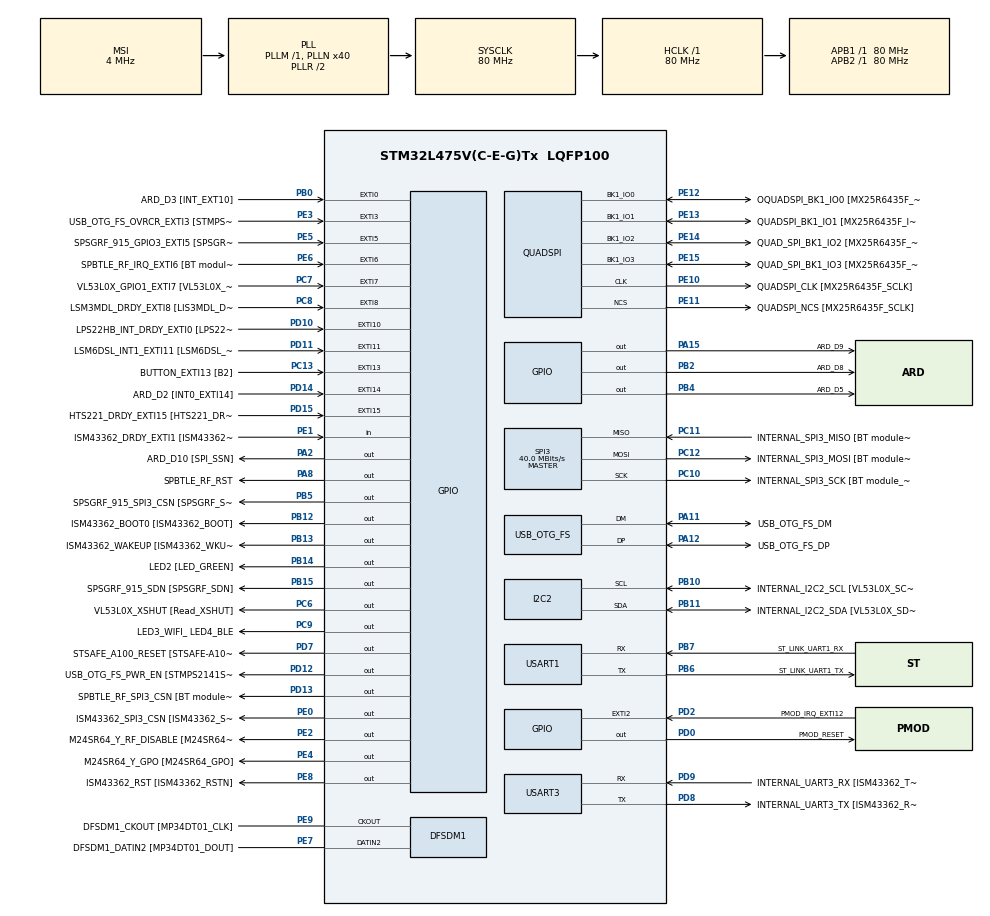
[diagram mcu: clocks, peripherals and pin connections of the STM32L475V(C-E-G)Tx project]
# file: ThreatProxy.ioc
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Mcu.Family=STM32L4
Mcu.Name=STM32L475V(C-E-G)Tx
Mcu.Package=LQFP100
NVIC.EXTI15_10_IRQn=true\:0\:0\:false\:false\:true\:true\:true\:true
NVIC.EXTI9_5_IRQn=true\:0\:0\:false\:false\:true\:true\:true\:true
NVIC.PriorityGroup=NVIC_PRIORITYGROUP_4
PA0.GPIO_Label=ARD_D1 [UART4_TX]
PA0.Signal=UART4_TX
PA1.GPIO_Label=ARD_D0 [UART4_RX]
PA1.Signal=UART4_RX
PA10.GPIO_Label=USB_OTG_FS_ID
PA10.Signal=USB_OTG_FS_ID
PA11.GPIO_Label=USB_OTG_FS_DM
PA11.Mode=Device_Only
PA11.Signal=USB_OTG_FS_DM
PA12.GPIO_Label=USB_OTG_FS_DP
PA12.Mode=Device_Only
PA12.Signal=USB_OTG_FS_DP
PA13\ (JTMS-SWDIO).GPIO_Label=SYS_JTMS_SWDIO
PA13\ (JTMS-SWDIO).Mode=Serial_Wire
PA13\ (JTMS-SWDIO).Signal=SYS_JTMS-SWDIO
PA14\ (JTCK-SWCLK).GPIO_Label=SYS_JTCK_SWCLK
PA14\ (JTCK-SWCLK).Mode=Serial_Wire
PA14\ (JTCK-SWCLK).Signal=SYS_JTCK-SWCLK
PA15\ (JTDI).GPIO_Label=ARD_D9
PA15\ (JTDI).Signal=GPIO_Output
PA2.GPIO_Label=ARD_D10 [SPI_SSN]
PA2.Signal=GPIO_Output
PA3.GPIO_Label=ARD_D4
PA3.Signal=S_TIM2_CH4
PA4.GPIO_Label=ARD_D7
PA4.Signal=ADCx_IN9
PA5.GPIO_Label=ARD_D13 [SPI1_SCK]
PA5.Signal=SPI1_SCK
PA6.GPIO_Label=ARD_D12 [SPI1_MISO]
PA6.Signal=SPI1_MISO
PA7.GPIO_Label=ARD_D11 [SPI1_MOSI]
PA7.Signal=SPI1_MOSI
PA8.GPIO_Label=SPBTLE_RF_RST
PA8.Signal=GPIO_Output
PA9.GPIO_Label=USB_OTG_FS_VBUS [STMPS2141STR_OUT]
PA9.Signal=USB_OTG_FS_VBUS
PB0.GPIO_Label=ARD_D3 [INT_EXT10]
PB0.Signal=GPXTI0
PB1.GPIO_Label=ARD_D6 [ADC1_IN6]
PB1.Signal=ADCx_IN16
PB10.GPIO_Label=INTERNAL_I2C2_SCL [VL53L0X_SCL]
PB10.GPIO_Pu=GPIO_PULLUP
PB10.Mode=I2C
PB10.Signal=I2C2_SCL
PB11.GPIO_Label=INTERNAL_I2C2_SDA [VL53L0X_SDA]
PB11.GPIO_Pu=GPIO_PULLUP
PB11.Mode=I2C
PB11.Signal=I2C2_SDA
PB12.GPIO_Label=ISM43362_BOOT0 [ISM43362_BOOT]
PB12.Signal=GPIO_Output
PB13.GPIO_Label=ISM43362_WAKEUP [ISM43362_WKUP]
PB13.Signal=GPIO_Output
PB14.GPIO_Label=LED2 [LED_GREEN]
PB14.Signal=GPIO_Output
PB15.GPIO_Label=SPSGRF_915_SDN [SPSGRF_SDN]
PB15.Signal=GPIO_Output
PB2.GPIO_Label=ARD_D8
PB2.Signal=GPIO_Output
PB3\ (JTDO-TRACESWO).GPIO_Label=SYS_JTD0_SWO
PB3\ (JTDO-TRACESWO).Signal=SYS_JTDO-SWO
PB4\ (NJTRST).GPIO_Label=ARD_D5
PB4\ (NJTRST).Signal=GPIO_Output
PB5.GPIO_Label=SPSGRF_915_SPI3_CSN [SPSGRF_SPI_CS]
PB5.PinState=GPIO_PIN_SET
PB5.Signal=GPIO_Output
PB6.GPIO_Label=ST_LINK_UART1_TX
PB6.Mode=Asynchronous
PB6.Signal=USART1_TX
PB7.GPIO_Label=ST_LINK_UART1_RX
PB7.Mode=Asynchronous
PB7.Signal=USART1_RX
PB8.GPIO_Label=ARD_D15 [I2C1_SCL]
PB8.Signal=I2C1_SCL
PB9.GPIO_Label=ARD_D14 [I2C1_SDA]
PB9.Signal=I2C1_SDA
PC0.GPIO_Label=ARD_A5 [ADC]
PC0.Signal=ADCx_IN1
PC1.GPIO_Label=ARD_A4 [ADC]
PC1.Signal=ADCx_IN2
PC10.GPIO_Label=INTERNAL_SPI3_SCK [BT module_SPI_SCLK] [ISM43362_SCK]
PC10.Mode=Full_Duplex_Master
PC10.Signal=SPI3_SCK
PC11.GPIO_Label=INTERNAL_SPI3_MISO [BT module_SPI_MISO] [ISM43362_MISO]
PC11.Mode=Full_Duplex_Master
PC11.Signal=SPI3_MISO
PC12.GPIO_Label=INTERNAL_SPI3_MOSI [BT module_SPI_MOSI] [ISM43362_MOSI]
PC12.Mode=Full_Duplex_Master
PC12.Signal=SPI3_MOSI
PC13.GPIO_Label=BUTTON_EXTI13 [B2]
PC13.GPIO_ModeDefaultEXTI=GPIO_MODE_IT_FALLING
PC13.Signal=GPXTI13
PC14-OSC32_IN\ (PC14).Mode=LSE-External-Oscillator
PC14-OSC32_IN\ (PC14).Signal=RCC_OSC32_IN
PC15-OSC32_OUT\ (PC15).Mode=LSE-External-Oscillator
PC15-OSC32_OUT\ (PC15).Signal=RCC_OSC32_OUT
PC2.GPIO_Label=ARD_A3 [ADC]
PC2.Signal=ADCx_IN3
PC3.GPIO_Label=ARD_A2 [ADC]
PC3.Signal=ADCx_IN4
PC4.GPIO_Label=ARD_A1 [ADC]
PC4.Signal=ADCx_IN13
PC5.GPIO_Label=ARD_A0 [ADC]
PC5.Signal=ADCx_IN14
PC6.GPIO_Label=VL53L0X_XSHUT [Read_XSHUT]
PC6.Signal=GPIO_Output
PC7.GPIO_Label=VL53L0X_GPIO1_EXTI7 [VL53L0X_GPIO1]
PC7.Signal=GPXTI7
PC8.GPIO_Label=LSM3MDL_DRDY_EXTI8 [LIS3MDL_DRDY]
PC8.Signal=GPXTI8
PC9.GPIO_Label=LED3_WIFI_ LED4_BLE
PC9.Signal=GPIO_Output
PD0.GPIO_Label=PMOD_RESET
PD0.Signal=GPIO_Output
PD1.GPIO_Label=PMOD_SPI2_SCK
PD1.Signal=SPI2_SCK
PD10.GPIO_Label=LPS22HB_INT_DRDY_EXTI0 [LPS22HB_INT_DRDY] 
PD10.Signal=GPXTI10
PD11.GPIO_Label=LSM6DSL_INT1_EXTI11 [LSM6DSL_INT1]
PD11.Signal=GPXTI11
PD12.GPIO_Label=USB_OTG_FS_PWR_EN [STMPS2141STR_EN]
PD12.Signal=GPIO_Output
PD13.GPIO_Label=SPBTLE_RF_SPI3_CSN [BT module_SPI_CS]
PD13.PinState=GPIO_PIN_SET
PD13.Signal=GPIO_Output
PD14.GPIO_Label=ARD_D2 [INT0_EXTI14]
PD14.Signal=GPXTI14
PD15.GPIO_Label=HTS221_DRDY_EXTI15 [HTS221_DRDY]
PD15.Signal=GPXTI15
PD2.GPIO_Label=PMOD_IRQ_EXTI12
PD2.Signal=GPXTI2
PD3.GPIO_Label=PMOD_UART2_CTS
PD3.Signal=USART2_CTS
PD4.GPIO_Label=PMOD_UART2_RTS
PD4.Signal=USART2_RTS
PD5.GPIO_Label=PMOD_UART2_TX
PD5.Signal=USART2_TX
PD6.GPIO_Label=PMOD_UART2_RX
PD6.Signal=USART2_RX
PD7.GPIO_Label=STSAFE_A100_RESET [STSAFE-A100_RESET]
PD7.Signal=GPIO_Output
PD8.GPIO_Label=INTERNAL_UART3_TX [ISM43362_RX]
PD8.Mode=Asynchronous
PD8.Signal=USART3_TX
PD9.GPIO_Label=INTERNAL_UART3_RX [ISM43362_TX]
PD9.Mode=Asynchronous
PD9.Signal=USART3_RX
PE0.GPIO_Label=ISM43362_SPI3_CSN [ISM43362_SSN]
PE0.PinState=GPIO_PIN_SET
PE0.Signal=GPIO_Output
PE1.GPIO_Label=ISM43362_DRDY_EXTI1 [ISM43362_DATARDY]
PE1.Signal=GPIO_Input
PE10.GPIO_Label=QUADSPI_CLK [MX25R6435F_SCLK]
PE10.Mode=Single Bank
PE10.Signal=QUADSPI_CLK
PE11.GPIO_Label=QUADSPI_NCS [MX25R6435F_SCLK]
PE11.Mode=Single Bank
PE11.Signal=QUADSPI_NCS
PE12.GPIO_Label=OQUADSPI_BK1_IO0 [MX25R6435F_IO0]
PE12.Mode=Single Bank
PE12.Signal=QUADSPI_BK1_IO0
PE13.GPIO_Label=QUADSPI_BK1_IO1 [MX25R6435F_IO1]
PE13.Mode=Single Bank
PE13.Signal=QUADSPI_BK1_IO1
PE14.GPIO_Label=QUAD_SPI_BK1_IO2 [MX25R6435F_IO2]
PE14.Mode=Single Bank
PE14.Signal=QUADSPI_BK1_IO2
PE15.GPIO_Label=QUAD_SPI_BK1_IO3 [MX25R6435F_IO3]
PE15.Mode=Single Bank
PE15.Signal=QUADSPI_BK1_IO3
PE2.GPIO_Label=M24SR64_Y_RF_DISABLE [M24SR64_RFDIS]
PE2.Signal=GPIO_Output
PE3.GPIO_Label=USB_OTG_FS_OVRCR_EXTI3 [STMPS2141STR_FAULT]
PE3.Signal=GPXTI3
PE4.GPIO_Label=M24SR64_Y_GPO [M24SR64_GPO]
PE4.Signal=GPIO_Output
PE5.GPIO_Label=SPSGRF_915_GPIO3_EXTI5 [SPSGRF_GPIO_3]
PE5.Signal=GPXTI5
PE6.GPIO_Label=SPBTLE_RF_IRQ_EXTI6 [BT module_SPI_IRQ]
PE6.Signal=GPXTI6
PE7.GPIO_Label=DFSDM1_DATIN2 [MP34DT01_DOUT]
PE7.Signal=S_DATAIN2DFSDM1
PE8.GPIO_Label=ISM43362_RST [ISM43362_RSTN]
PE8.Signal=GPIO_Output
PE9.GPIO_Label=DFSDM1_CKOUT [MP34DT01_CLK]
PE9.Signal=S_CKOUTDFSDM1
ProjectManager.HeapSize=0x200
ProjectManager.StackSize=0x400
ProjectManager.TargetToolchain=CMake
QUADSPI.ClockPrescaler=2
QUADSPI.FifoThreshold=4
QUADSPI.FlashSize=23
QUADSPI.SampleShifting=QSPI_SAMPLE_SHIFTING_HALFCYCLE
RCC.ADCFreq_Value=48000000
RCC.AHBFreq_Value=80000000
RCC.APB1Freq_Value=80000000
RCC.APB1TimFreq_Value=80000000
RCC.APB2Freq_Value=80000000
RCC.APB2TimFreq_Value=80000000
RCC.CortexFreq_Value=80000000
RCC.HCLKFreq_Value=80000000
RCC.HSE_VALUE=8000000
RCC.HSI_VALUE=16000000
RCC.MSI_VALUE=4000000
RCC.PLLN=40
RCC.PLLSAI1N=24
RCC.SYSCLKFreq_VALUE=80000000
RCC.SYSCLKSource=RCC_SYSCLKSOURCE_PLLCLK
RCC.USBFreq_Value=48000000
RCC.VCOOutputFreq_Value=160000000
SH.ADCx_IN1.0=ADC1_IN1
SH.ADCx_IN13.0=ADC1_IN13
SH.ADCx_IN14.0=ADC1_IN14
SH.ADCx_IN16.0=ADC1_IN16
SH.ADCx_IN2.0=ADC1_IN2
SH.ADCx_IN3.0=ADC1_IN3
SH.ADCx_IN4.0=ADC1_IN4
SH.ADCx_IN9.0=ADC1_IN9
SH.S_CKOUTDFSDM1.0=DFSDM1_CKOUT,CKOUT
SH.S_CKOUTDFSDM1.1=DFSDM1_CKOUT,PDM_SPI_Input_from_ch12_and_Internal_Clock
SH.S_DATAIN2DFSDM1.0=DFSDM1_DATIN2,PDM_SPI_Input_from_ch12_and_Internal_Clock
SH.S_TIM2_CH4.0=TIM2_CH4
SPI3.CalculateBaudRate=40.0 MBits/s
SPI3.Direction=SPI_DIRECTION_2LINES
SPI3.Mode=SPI_MODE_MASTER
SPI3.VirtualType=VM_MASTER
USART1.VirtualMode-Asynchronous=VM_ASYNC
USART3.VirtualMode-Asynchronous=VM_ASYNC
USB_OTG_FS.VirtualMode=Device_Only
board=B-L475E-IOT01A1

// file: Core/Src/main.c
/* USER CODE BEGIN Header */
/**
  ******************************************************************************
  * @file           : main.c
  * @brief          : Main program body
  ******************************************************************************
  * @attention
  *
  * Copyright (c) 2026 STMicroelectronics.
  * All rights reserved.
  *
  * This software is licensed under terms that can be found in the LICENSE file
  * in the root directory of this software component.
  * If no LICENSE file comes with this software, it is provided AS-IS.
  *
  ******************************************************************************
  */
/* USER CODE END Header */
#include "main.h"
#include "secrets.h"
#include <string.h>
#include <stdlib.h>

DFSDM_Channel_HandleTypeDef hdfsdm1_channel1;

I2C_HandleTypeDef hi2c2;

QSPI_HandleTypeDef hqspi;

SPI_HandleTypeDef hspi3;

UART_HandleTypeDef huart1;
UART_HandleTypeDef huart3;

PCD_HandleTypeDef hpcd_USB_OTG_FS;

void SystemClock_Config(void);
static void MX_GPIO_Init(void);
static void MX_DFSDM1_Init(void);
static void MX_I2C2_Init(void);
static void MX_QUADSPI_Init(void);
static void MX_SPI3_Init(void);
static void MX_USART1_UART_Init(void);
static void MX_USART3_UART_Init(void);
static void MX_USB_OTG_FS_PCD_Init(void);

/* USER CODE BEGIN 0 */
#include <stdio.h>
int _write(int file, char *ptr, int len) {

    HAL_UART_Transmit(&huart1, (uint8_t *)ptr, len, HAL_MAX_DELAY);
    return len;
}
/* USER CODE END 0 */

void Inventek_Send_Command(SPI_HandleTypeDef *hspi, const char *cmd) {
    uint8_t tx_buf[128] = {0};
    uint16_t len = strlen(cmd);
    strcpy((char*)tx_buf, cmd);

    if (len % 2 != 0) {
        tx_buf[len] = '\n';
        len++;
    }

    for (int i = 0; i < len; i += 2) {
        uint8_t temp = tx_buf[i];
        tx_buf[i] = tx_buf[i+1];
        tx_buf[i+1] = temp;
    }

    HAL_GPIO_WritePin(GPIOE, GPIO_PIN_0, GPIO_PIN_RESET);
    HAL_Delay(1);
    HAL_SPI_Transmit(hspi, tx_buf, len, 100);
    HAL_GPIO_WritePin(GPIOE, GPIO_PIN_0, GPIO_PIN_SET);
    HAL_Delay(10);
}

void Inventek_Drain_Response(SPI_HandleTypeDef *hspi) {
    uint32_t wait_timeout = HAL_GetTick() + 1000;

    while(HAL_GPIO_ReadPin(GPIOE, GPIO_PIN_1) == GPIO_PIN_RESET && HAL_GetTick() < wait_timeout);

    if(HAL_GPIO_ReadPin(GPIOE, GPIO_PIN_1) == GPIO_PIN_SET) {
        HAL_GPIO_WritePin(GPIOE, GPIO_PIN_0, GPIO_PIN_RESET);
        uint8_t dummy[2] = {0x0A, 0x0A}, rx[2] = {0};
        uint32_t drain_timeout = HAL_GetTick() + 2000;

        printf("  -> Radio replied: ");
        while(HAL_GPIO_ReadPin(GPIOE, GPIO_PIN_1) == GPIO_PIN_SET && HAL_GetTick() < drain_timeout) {
            HAL_SPI_TransmitReceive(hspi, dummy, rx, 2, 10);

            if((rx[1] >= 0x20 && rx[1] <= 0x7E) || rx[1] == '\r' || rx[1] == '\n') printf("%c", rx[1]);
            if((rx[0] >= 0x20 && rx[0] <= 0x7E) || rx[0] == '\r' || rx[0] == '\n') printf("%c", rx[0]);
        }
        HAL_GPIO_WritePin(GPIOE, GPIO_PIN_0, GPIO_PIN_SET);
    } else {
        printf("  -> [!] No response from radio.\r\n");
    }
    HAL_Delay(50);
}

typedef struct {
    uint16_t magic;
    uint32_t src_ip;
    uint32_t dst_ip;
    uint16_t src_port;
    uint16_t dst_port;
    uint8_t  protocol;
} __attribute__((packed)) FlowTuple;

#define IP_PARTS(ip) (uint8_t)(ip), (uint8_t)((ip) >> 8), (uint8_t)((ip) >> 16), (uint8_t)((ip) >> 24)

uint32_t MurmurHash3_32(const void* key, int len, uint32_t seed) {
    const uint8_t* data = (const uint8_t*)key;
    const int nblocks = len / 4;
    uint32_t h1 = seed;
    const uint32_t c1 = 0xcc9e2d51;
    const uint32_t c2 = 0x1b873593;

    const uint32_t* blocks = (const uint32_t*)(data + nblocks * 4);
    for (int i = -nblocks; i; i++) {
        uint32_t k1 = blocks[i];
        k1 *= c1;
        k1 = (k1 << 15) | (k1 >> (32 - 15));
        k1 *= c2;

        h1 ^= k1;
        h1 = (h1 << 13) | (h1 >> (32 - 13));
        h1 = h1 * 5 + 0xe6546b64;
    }

    const uint8_t* tail = (const uint8_t*)(data + nblocks * 4);
    uint32_t k1 = 0;
    switch (len & 3) {
        case 3: k1 ^= tail[2] << 16;
        case 2: k1 ^= tail[1] << 8;
        case 1: k1 ^= tail[0];
                k1 *= c1;
                k1 = (k1 << 15) | (k1 >> (32 - 15));
                k1 *= c2;
                h1 ^= k1;
    }

    h1 ^= len;
    h1 ^= h1 >> 16;
    h1 *= 0x85ebca6b;
    h1 ^= h1 >> 13;
    h1 *= 0xc2b2ae35;
    h1 ^= h1 >> 16;

    return h1;
}

#define MAX_STATES 50
#define ALPHABET_SIZE 256

int goto_fn[MAX_STATES][ALPHABET_SIZE];
int out_fn[MAX_STATES];
int num_states = 1;
void build_aho_corasick() {
    memset(goto_fn, -1, sizeof(goto_fn));
    memset(out_fn, 0, sizeof(out_fn));

    // --- REAL CVE HEX SIGNATURES ---
    // 1. Log4Shell JNDI Trigger ("${jndi:")
    const uint8_t sig_log4j[] = {0x24, 0x7B, 0x6A, 0x6E, 0x64, 0x69, 0x3A};
    // 2. x86 Buffer Overflow (NOP Sled)
    const uint8_t sig_nop[]   = {0x90, 0x90, 0x90, 0x90, 0x90, 0x90, 0x90, 0x90};
    // 3. Heartbleed Malformed TLS Heartbeat
    const uint8_t sig_heart[] = {0x18, 0x03, 0x02, 0x00, 0x03};

    const uint8_t* signatures[] = {sig_log4j, sig_nop, sig_heart};
    const int sig_lengths[] = {sizeof(sig_log4j), sizeof(sig_nop), sizeof(sig_heart)};
    int num_signatures = 3;

    // Build the state machine strictly using raw byte values (0x00 - 0xFF)
    for (int i = 0; i < num_signatures; i++) {
        int curr_state = 0;
        for (int j = 0; j < sig_lengths[i]; j++) {
            uint8_t c = signatures[i][j]; // Extract exact hex byte
            if (goto_fn[curr_state][c] == -1) {
                goto_fn[curr_state][c] = num_states++;
            }
            curr_state = goto_fn[curr_state][c];
        }
        out_fn[curr_state] = 1;
    }

    for (int i = 0; i < ALPHABET_SIZE; i++) {
        if (goto_fn[0][i] == -1) goto_fn[0][i] = 0;
    }
}
//defined int goto_fn[MAX_STATES][256], created a grid in memory.The Y-axis is your current state.
// The X-axis has exactly 256 slots. This perfectly matches the 256 possible values of an 8-bit byte.
// When the processor reads a byte from the incoming payload let's say it reads 0x18  the first byte of the TLS Heartbleed trigger it does not ask, "
// Does 0x18 equal 0x18?" Instead, the processor takes the literal integer value of 0x18 (which is 24 in decimal) and uses it as the Column Number.It immediately
//  jumps to Row 0, Column 24 in the memory matrix. Sitting inside that exact cell is a pre-calculated integer telling the board what the next state is
//  brilliant for an edge proxy:Because the raw packet data is being used as a literal memory address pointer,
// the time complexity to evaluate a byte is $O(1)$. It takes exactly one clock cycle to fetch the next state, regardless of whether you have 3 signatures
//  loaded or 14,000
// When you create a 2D array in C like goto_fn[state][byte], the compiler translates that into a literal physical address in the RAM.
// When the processor reads a byte from the network (let's say 0x18), it does not loop through a list looking for 0x18. Instead, the ALUs
// inside the ARM Cortex execute a hardwired calculation:
int aho_corasick_search(const uint8_t* payload, int len) {
    int curr_state = 0;
    for (int i = 0; i < len; i++) {
        curr_state = goto_fn[curr_state][payload[i]];
        if (curr_state == -1) curr_state = 0;

        if (out_fn[curr_state]) {
            return i;
        }
    }
    return -1;
}

int main(void)
{

  /* MCU Configuration--------------------------------------------------------*/

  /* Reset of all peripherals, Initializes the Flash interface and the Systick. */
  HAL_Init();

  /* Configure the system clock */
  SystemClock_Config();

  /* Initialize all configured peripherals */
  MX_GPIO_Init();
  MX_DFSDM1_Init();
  MX_I2C2_Init();
  MX_QUADSPI_Init();
  MX_SPI3_Init();
  MX_USART1_UART_Init();
  MX_USART3_UART_Init();
  MX_USB_OTG_FS_PCD_Init();

  printf("\r\n[*]ISOLATING AND WAKING THE RADIO\r\n");

  HAL_GPIO_WritePin(GPIOB, GPIO_PIN_12, GPIO_PIN_RESET);

  HAL_GPIO_WritePin(GPIOE, GPIO_PIN_8, GPIO_PIN_RESET);
  HAL_Delay(50);

  HAL_GPIO_WritePin(GPIOB, GPIO_PIN_13, GPIO_PIN_SET);

  HAL_GPIO_WritePin(GPIOE, GPIO_PIN_0, GPIO_PIN_RESET);
  HAL_Delay(10);

  HAL_GPIO_WritePin(GPIOE, GPIO_PIN_8, GPIO_PIN_SET);

  HAL_Delay(50);

  HAL_GPIO_WritePin(GPIOE, GPIO_PIN_0, GPIO_PIN_SET);

  HAL_Delay(500);
  printf("[*] Draining internal boot prompt\r\n");
  Inventek_Drain_Response(&hspi3);
  printf("[*] Boot prompt cleared. Radio is ready.\r\n");

 printf("\r\n[*] Configuring Wi-Fi Credentials\r\n");
  char cmd_buffer[128];

  snprintf(cmd_buffer, sizeof(cmd_buffer), "C1=%s\r", WIFI_SSID);
  Inventek_Send_Command(&hspi3, cmd_buffer);
  Inventek_Drain_Response(&hspi3);

  snprintf(cmd_buffer, sizeof(cmd_buffer), "C2=%s\r", WIFI_PASS);
  Inventek_Send_Command(&hspi3, cmd_buffer);
  Inventek_Drain_Response(&hspi3);

  Inventek_Send_Command(&hspi3, "C3=3\r");
  Inventek_Drain_Response(&hspi3);

  Inventek_Send_Command(&hspi3, "C4=1\r");
  Inventek_Drain_Response(&hspi3);

  printf("\r\n[*] Attempting to join network and pull DHCP lease\r\n");
  Inventek_Send_Command(&hspi3, "C0\r");

  uint32_t join_timeout = HAL_GetTick() + 35000;
  uint8_t joined = 0;

  printf("\r\nLIVE NETWORK LOG\r\n");

  while(HAL_GetTick() < join_timeout && !joined) {

      if(HAL_GPIO_ReadPin(GPIOE, GPIO_PIN_1) == GPIO_PIN_SET) {

          HAL_GPIO_WritePin(GPIOE, GPIO_PIN_0, GPIO_PIN_RESET);

          uint8_t dummy_word[2] = {0x0A, 0x0A}, rx_word[2] = {0};
          uint32_t read_timeout = HAL_GetTick() + 2000;

          while(HAL_GPIO_ReadPin(GPIOE, GPIO_PIN_1) == GPIO_PIN_SET && HAL_GetTick() < read_timeout) {
              HAL_SPI_TransmitReceive(&hspi3, dummy_word, rx_word, 2, 10);

              if((rx_word[1] >= 0x20 && rx_word[1] <= 0x7E) || rx_word[1] == '\r' || rx_word[1] == '\n') {
                  printf("%c", rx_word[1]);

                  if(rx_word[1] == '>') joined = 1;
              }
              if((rx_word[0] >= 0x20 && rx_word[0] <= 0x7E) || rx_word[0] == '\r' || rx_word[0] == '\n') {
                  printf("%c", rx_word[0]);

                  if(rx_word[0] == '>') joined = 1;
              }
          }

          HAL_GPIO_WritePin(GPIOE, GPIO_PIN_0, GPIO_PIN_SET);
          HAL_Delay(50);
      }
  }

  printf("\r\nEND\r\n");

  Inventek_Send_Command(&hspi3, "P1=0\r");
  Inventek_Drain_Response(&hspi3);

  Inventek_Send_Command(&hspi3, "P2=54321\r");
  Inventek_Drain_Response(&hspi3);

  Inventek_Send_Command(&hspi3, "R1=1\r");
  Inventek_Drain_Response(&hspi3);

  Inventek_Send_Command(&hspi3, "P5=1\r");
  Inventek_Drain_Response(&hspi3);
  printf("\r\n[*] Compiling Aho-Corasick DPI State Machine\r\n");
  build_aho_corasick();

  printf("\r\n[*] Vertex Active. Awaiting Incoming Flows\r\n");

  static uint32_t last_heartbeat = 0;
  static uint32_t loop_counter = 0;

  while (1)
  {
      uint8_t demo_payload[53] = {
          0x55, 0xAA, // Magic Header
          0x00, 0x00, 0x00, 0x00, // Placeholder for Src IP
          0xC0, 0xA8, 0x01, 0xE9, // Dst IP: 192.168.1.233 (The Proxy VIP)
          0xC0, 0x00, // Src Port placeholder
          0xD3, 0xD4, // Dst Port: 54321
          0x06,       // Protocol: TCP
          // ... trailing payload bytes
      };

      // --- LIVE DISTRIBUTED ATTACK SIMULATION ---
      // Generate a completely random global Source IP to simulate a distributed botnet
      demo_payload[2] = (uint8_t)(rand() % 223 + 1); // 1-223 (Public IP ranges)
      demo_payload[3] = (uint8_t)(rand() % 256);
      demo_payload[4] = (uint8_t)(rand() % 256);
      demo_payload[5] = (uint8_t)(rand() % 256);

      FlowTuple current_flow;
      memcpy(&current_flow, &demo_payload[0], sizeof(FlowTuple));

      // Dynamically increment the port
      static uint16_t dynamic_src_port = 49152;
      current_flow.src_port = dynamic_src_port++;
      current_flow.dst_port = 54321;

      uint32_t flow_id = MurmurHash3_32(&current_flow.src_ip, sizeof(FlowTuple) - 2, 0x12345678);
      //route this flow without using a memoryheavy state table.
      // We take that extracted 5-Tuple and pass it by reference into a murmurhash3 algorithm. This is a noncryptographic hash function
      // optimized for silicon. It crushes the IP and Port data down into a highly unique, deterministic 32bit integer,
      // store here"

      printf("L4 FLOW INTERCEPTED \r\n");
      printf("Src IP: %u.%u.%u.%u | Dst IP: %u.%u.%u.%u \r\n",
             IP_PARTS(current_flow.src_ip), IP_PARTS(current_flow.dst_ip));
      printf("Protocol: %u | Src Port: %u | Dst Port: %u \r\n",
             current_flow.protocol, current_flow.src_port, current_flow.dst_port);
      printf("Flow Identity (Murmur32): 0x%08lX \r\n", flow_id);

      printf("\r\n[*] Executing ECMP Routing Heuristic\r\n");
      uint8_t available_egress_paths = 3;
      //The processor takes that 32bit flow_id and runs a modulo operation against our available virtual egress paths in this case, three.
      //Because the murmurHash is strictly deterministic, every single packet originating from the same client session will result in the exact same 32
      // bit hash, and therefore, the exact same modulo remainder. This guarantees perfect TCP session persistence.
      uint8_t selected_route = flow_id % available_egress_paths;

      switch(selected_route) {
          case 0: printf("[+] ROUTING DECISION: Flow assigned to Egress Path A (eth0)\r\n"); break;
          case 1: printf("[+] ROUTING DECISION: Flow assigned to Egress Path B (eth1)\r\n"); break;
          case 2: printf("[+] ROUTING DECISION: Flow assigned to Egress Path C (eth2)\r\n"); break;
      }

      printf("\r\n[*] Executing Aho-Corasick DPI Scrub\r\n");

      static int packet_count = 0;
      packet_count++;

      if (packet_count % 2 == 0) {
          demo_payload[12] = 0x24; demo_payload[13] = 0x7B;
          demo_payload[14] = 0x6A; demo_payload[15] = 0x6E;
          demo_payload[16] = 0x64; demo_payload[17] = 0x69;
          demo_payload[18] = 0x3A;
      } else {
          // Standard HTTP GET bytes
          demo_payload[12] = 0x47; demo_payload[13] = 0x45;
          demo_payload[14] = 0x54; demo_payload[15] = 0x20;
          demo_payload[16] = 0x2F; demo_payload[17] = 0x20;
          demo_payload[18] = 0x48;
      }

      int threat_offset = aho_corasick_search(demo_payload, sizeof(demo_payload));

      if (threat_offset != -1) {
          printf("\r\n[!] THREAT DETECTED: Malicious Signature hit at memory offset [0x%02X]\r\n", threat_offset);
          printf("[*] ISOLATING MALFORMED PAYLOAD BLOCK:\r\n");

          printf("    [HEX] ");
          for(int i = 8; i < 20; i++) {
              printf("%02X ", demo_payload[i]);
          }

          printf("\r\n\r\n[!] ACTION: Connection Terminated. TCP Flow Dropped.\r\n");
      } else {
          printf("[+] Payload Clean. Forwarding to vertex...\r\n");
      }
      HAL_Delay(4000);
  /* USER CODE END 3 */
}
}

void SystemClock_Config(void)
{
  RCC_OscInitTypeDef RCC_OscInitStruct = {0};
  RCC_ClkInitTypeDef RCC_ClkInitStruct = {0};

  /** Configure the main internal regulator output voltage
  */
  if (HAL_PWREx_ControlVoltageScaling(PWR_REGULATOR_VOLTAGE_SCALE1) != HAL_OK)
  {
    Error_Handler();
  }

  /** Configure LSE Drive Capability
  */
  HAL_PWR_EnableBkUpAccess();
  __HAL_RCC_LSEDRIVE_CONFIG(RCC_LSEDRIVE_LOW);

  /** Initializes the RCC Oscillators according to the specified parameters
  * in the RCC_OscInitTypeDef structure.
  */
  RCC_OscInitStruct.OscillatorType = RCC_OSCILLATORTYPE_LSE|RCC_OSCILLATORTYPE_MSI;
  RCC_OscInitStruct.LSEState = RCC_LSE_ON;
  RCC_OscInitStruct.MSIState = RCC_MSI_ON;
  RCC_OscInitStruct.MSICalibrationValue = 0;
  RCC_OscInitStruct.MSIClockRange = RCC_MSIRANGE_6;
  RCC_OscInitStruct.PLL.PLLState = RCC_PLL_ON;
  RCC_OscInitStruct.PLL.PLLSource = RCC_PLLSOURCE_MSI;
  RCC_OscInitStruct.PLL.PLLM = 1;
  RCC_OscInitStruct.PLL.PLLN = 40;
  RCC_OscInitStruct.PLL.PLLP = RCC_PLLP_DIV7;
  RCC_OscInitStruct.PLL.PLLQ = RCC_PLLQ_DIV2;
  RCC_OscInitStruct.PLL.PLLR = RCC_PLLR_DIV2;
  if (HAL_RCC_OscConfig(&RCC_OscInitStruct) != HAL_OK)
  {
    Error_Handler();
  }

  /** Initializes the CPU, AHB and APB buses clocks
  */
  RCC_ClkInitStruct.ClockType = RCC_CLOCKTYPE_HCLK|RCC_CLOCKTYPE_SYSCLK
                              |RCC_CLOCKTYPE_PCLK1|RCC_CLOCKTYPE_PCLK2;
  RCC_ClkInitStruct.SYSCLKSource = RCC_SYSCLKSOURCE_PLLCLK;
  RCC_ClkInitStruct.AHBCLKDivider = RCC_SYSCLK_DIV1;
  RCC_ClkInitStruct.APB1CLKDivider = RCC_HCLK_DIV1;
  RCC_ClkInitStruct.APB2CLKDivider = RCC_HCLK_DIV1;

  if (HAL_RCC_ClockConfig(&RCC_ClkInitStruct, FLASH_LATENCY_4) != HAL_OK)
  {
    Error_Handler();
  }

  /** Enable MSI Auto calibration
  */
  HAL_RCCEx_EnableMSIPLLMode();
}

static void MX_DFSDM1_Init(void)
{

  hdfsdm1_channel1.Instance = DFSDM1_Channel1;
  hdfsdm1_channel1.Init.OutputClock.Activation = ENABLE;
  hdfsdm1_channel1.Init.OutputClock.Selection = DFSDM_CHANNEL_OUTPUT_CLOCK_SYSTEM;
  hdfsdm1_channel1.Init.OutputClock.Divider = 2;
  hdfsdm1_channel1.Init.Input.Multiplexer = DFSDM_CHANNEL_EXTERNAL_INPUTS;
  hdfsdm1_channel1.Init.Input.DataPacking = DFSDM_CHANNEL_STANDARD_MODE;
  hdfsdm1_channel1.Init.Input.Pins = DFSDM_CHANNEL_FOLLOWING_CHANNEL_PINS;
  hdfsdm1_channel1.Init.SerialInterface.Type = DFSDM_CHANNEL_SPI_RISING;
  hdfsdm1_channel1.Init.SerialInterface.SpiClock = DFSDM_CHANNEL_SPI_CLOCK_INTERNAL;
  hdfsdm1_channel1.Init.Awd.FilterOrder = DFSDM_CHANNEL_FASTSINC_ORDER;
  hdfsdm1_channel1.Init.Awd.Oversampling = 1;
  hdfsdm1_channel1.Init.Offset = 0;
  hdfsdm1_channel1.Init.RightBitShift = 0x00;
  if (HAL_DFSDM_ChannelInit(&hdfsdm1_channel1) != HAL_OK)
  {
    Error_Handler();
  }

}

static void MX_I2C2_Init(void)
{

  hi2c2.Instance = I2C2;
  hi2c2.Init.Timing = 0x00000E14;
  hi2c2.Init.OwnAddress1 = 0;
  hi2c2.Init.AddressingMode = I2C_ADDRESSINGMODE_7BIT;
  hi2c2.Init.DualAddressMode = I2C_DUALADDRESS_DISABLE;
  hi2c2.Init.OwnAddress2 = 0;
  hi2c2.Init.OwnAddress2Masks = I2C_OA2_NOMASK;
  hi2c2.Init.GeneralCallMode = I2C_GENERALCALL_DISABLE;
  hi2c2.Init.NoStretchMode = I2C_NOSTRETCH_DISABLE;
  if (HAL_I2C_Init(&hi2c2) != HAL_OK)
  {
    Error_Handler();
  }

  /** Configure Analogue filter
  */
  if (HAL_I2CEx_ConfigAnalogFilter(&hi2c2, I2C_ANALOGFILTER_ENABLE) != HAL_OK)
  {
    Error_Handler();
  }

  /** Configure Digital filter
  */
  if (HAL_I2CEx_ConfigDigitalFilter(&hi2c2, 0) != HAL_OK)
  {
    Error_Handler();
  }

}

static void MX_QUADSPI_Init(void)
{

  /* QUADSPI parameter configuration*/
  hqspi.Instance = QUADSPI;
  hqspi.Init.ClockPrescaler = 2;
  hqspi.Init.FifoThreshold = 4;
  hqspi.Init.SampleShifting = QSPI_SAMPLE_SHIFTING_HALFCYCLE;
  hqspi.Init.FlashSize = 23;
  hqspi.Init.ChipSelectHighTime = QSPI_CS_HIGH_TIME_1_CYCLE;
  hqspi.Init.ClockMode = QSPI_CLOCK_MODE_0;
  if (HAL_QSPI_Init(&hqspi) != HAL_OK)
  {
    Error_Handler();
  }

}

static void MX_SPI3_Init(void)
{

  /* SPI3 parameter configuration*/
  hspi3.Instance = SPI3;
  hspi3.Init.Mode = SPI_MODE_MASTER;
  hspi3.Init.Direction = SPI_DIRECTION_2LINES;
  hspi3.Init.DataSize = SPI_DATASIZE_8BIT;
  hspi3.Init.CLKPolarity = SPI_POLARITY_LOW;
  hspi3.Init.CLKPhase = SPI_PHASE_1EDGE;
  hspi3.Init.NSS = SPI_NSS_SOFT;
  hspi3.Init.BaudRatePrescaler = SPI_BAUDRATEPRESCALER_8;
  hspi3.Init.FirstBit = SPI_FIRSTBIT_MSB;
  hspi3.Init.TIMode = SPI_TIMODE_DISABLE;
  hspi3.Init.CRCCalculation = SPI_CRCCALCULATION_DISABLE;
  hspi3.Init.CRCPolynomial = 7;
  hspi3.Init.CRCLength = SPI_CRC_LENGTH_DATASIZE;
  hspi3.Init.NSSPMode = SPI_NSS_PULSE_ENABLE;
  if (HAL_SPI_Init(&hspi3) != HAL_OK)
  {
    Error_Handler();
  }

}

static void MX_USART1_UART_Init(void)
{

  huart1.Instance = USART1;
  huart1.Init.BaudRate = 115200;
  huart1.Init.WordLength = UART_WORDLENGTH_8B;
  huart1.Init.StopBits = UART_STOPBITS_1;
  huart1.Init.Parity = UART_PARITY_NONE;
  huart1.Init.Mode = UART_MODE_TX_RX;
  huart1.Init.HwFlowCtl = UART_HWCONTROL_NONE;
  huart1.Init.OverSampling = UART_OVERSAMPLING_16;
  huart1.Init.OneBitSampling = UART_ONE_BIT_SAMPLE_DISABLE;
  huart1.AdvancedInit.AdvFeatureInit = UART_ADVFEATURE_NO_INIT;
  if (HAL_UART_Init(&huart1) != HAL_OK)
  {
    Error_Handler();
  }

}

static void MX_USART3_UART_Init(void)
{

  huart3.Instance = USART3;
  huart3.Init.BaudRate = 115200;
  huart3.Init.WordLength = UART_WORDLENGTH_8B;
  huart3.Init.StopBits = UART_STOPBITS_1;
  huart3.Init.Parity = UART_PARITY_NONE;
  huart3.Init.Mode = UART_MODE_TX_RX;
  huart3.Init.HwFlowCtl = UART_HWCONTROL_NONE;
  huart3.Init.OverSampling = UART_OVERSAMPLING_16;
  huart3.Init.OneBitSampling = UART_ONE_BIT_SAMPLE_DISABLE;
  huart3.AdvancedInit.AdvFeatureInit = UART_ADVFEATURE_NO_INIT;
  if (HAL_UART_Init(&huart3) != HAL_OK)
  {
    Error_Handler();
  }

}

static void MX_USB_OTG_FS_PCD_Init(void)
{

  hpcd_USB_OTG_FS.Instance = USB_OTG_FS;
  hpcd_USB_OTG_FS.Init.dev_endpoints = 6;
  hpcd_USB_OTG_FS.Init.speed = PCD_SPEED_FULL;
  hpcd_USB_OTG_FS.Init.phy_itface = PCD_PHY_EMBEDDED;
  hpcd_USB_OTG_FS.Init.Sof_enable = DISABLE;
  hpcd_USB_OTG_FS.Init.low_power_enable = DISABLE;
  hpcd_USB_OTG_FS.Init.lpm_enable = DISABLE;
  hpcd_USB_OTG_FS.Init.battery_charging_enable = DISABLE;
  hpcd_USB_OTG_FS.Init.use_dedicated_ep1 = DISABLE;
  hpcd_USB_OTG_FS.Init.vbus_sensing_enable = DISABLE;
  if (HAL_PCD_Init(&hpcd_USB_OTG_FS) != HAL_OK)
  {
    Error_Handler();
  }

}

static void MX_GPIO_Init(void)
{
  GPIO_InitTypeDef GPIO_InitStruct = {0};

  /* GPIO Ports Clock Enable */
  __HAL_RCC_GPIOE_CLK_ENABLE();
  __HAL_RCC_GPIOC_CLK_ENABLE();
  __HAL_RCC_GPIOA_CLK_ENABLE();
  __HAL_RCC_GPIOB_CLK_ENABLE();
  __HAL_RCC_GPIOD_CLK_ENABLE();

  /*Configure GPIO pin Output Level */
  HAL_GPIO_WritePin(GPIOE, M24SR64_Y_RF_DISABLE_Pin|M24SR64_Y_GPO_Pin|ISM43362_RST_Pin, GPIO_PIN_RESET);

  /*Configure GPIO pin Output Level */
  HAL_GPIO_WritePin(GPIOA, ARD_D10_Pin|SPBTLE_RF_RST_Pin|ARD_D9_Pin, GPIO_PIN_RESET);

  /*Configure GPIO pin Output Level */
  HAL_GPIO_WritePin(GPIOB, ARD_D8_Pin|ISM43362_BOOT0_Pin|ISM43362_WAKEUP_Pin|LED2_Pin
                          |SPSGRF_915_SDN_Pin|ARD_D5_Pin, GPIO_PIN_RESET);

  /*Configure GPIO pin Output Level */
  HAL_GPIO_WritePin(GPIOD, USB_OTG_FS_PWR_EN_Pin|PMOD_RESET_Pin|STSAFE_A100_RESET_Pin, GPIO_PIN_RESET);

  /*Configure GPIO pin Output Level */
  HAL_GPIO_WritePin(SPBTLE_RF_SPI3_CSN_GPIO_Port, SPBTLE_RF_SPI3_CSN_Pin, GPIO_PIN_SET);

  /*Configure GPIO pin Output Level */
  HAL_GPIO_WritePin(GPIOC, VL53L0X_XSHUT_Pin|LED3_WIFI__LED4_BLE_Pin, GPIO_PIN_RESET);

  /*Configure GPIO pin Output Level */
  HAL_GPIO_WritePin(SPSGRF_915_SPI3_CSN_GPIO_Port, SPSGRF_915_SPI3_CSN_Pin, GPIO_PIN_SET);

  /*Configure GPIO pin Output Level */
  HAL_GPIO_WritePin(ISM43362_SPI3_CSN_GPIO_Port, ISM43362_SPI3_CSN_Pin, GPIO_PIN_SET);

  HAL_GPIO_WritePin(GPIOB, GPIO_PIN_12, GPIO_PIN_RESET);
  HAL_GPIO_WritePin(GPIOB, GPIO_PIN_13, GPIO_PIN_RESET);

  /*Configure GPIO pins : M24SR64_Y_RF_DISABLE_Pin M24SR64_Y_GPO_Pin ISM43362_RST_Pin ISM43362_SPI3_CSN_Pin */
  GPIO_InitStruct.Pin = M24SR64_Y_RF_DISABLE_Pin|M24SR64_Y_GPO_Pin|ISM43362_RST_Pin|ISM43362_SPI3_CSN_Pin;
  GPIO_InitStruct.Mode = GPIO_MODE_OUTPUT_PP;
  GPIO_InitStruct.Pull = GPIO_NOPULL;
  GPIO_InitStruct.Speed = GPIO_SPEED_FREQ_LOW;
  HAL_GPIO_Init(GPIOE, &GPIO_InitStruct);

  GPIO_InitStruct.Pin = GPIO_PIN_12 | GPIO_PIN_13;
  GPIO_InitStruct.Mode = GPIO_MODE_OUTPUT_PP;
  GPIO_InitStruct.Pull = GPIO_NOPULL;
  GPIO_InitStruct.Speed = GPIO_SPEED_FREQ_LOW;
  HAL_GPIO_Init(GPIOB, &GPIO_InitStruct);

  /*Configure GPIO pins : USB_OTG_FS_OVRCR_EXTI3_Pin SPSGRF_915_GPIO3_EXTI5_Pin SPBTLE_RF_IRQ_EXTI6_Pin ISM43362_DRDY_EXTI1_Pin */
  GPIO_InitStruct.Pin = USB_OTG_FS_OVRCR_EXTI3_Pin|SPSGRF_915_GPIO3_EXTI5_Pin|SPBTLE_RF_IRQ_EXTI6_Pin|ISM43362_DRDY_EXTI1_Pin;
  GPIO_InitStruct.Mode = GPIO_MODE_INPUT;
  GPIO_InitStruct.Pull = GPIO_NOPULL;
  HAL_GPIO_Init(GPIOE, &GPIO_InitStruct);

  /*Configure GPIO pin : BUTTON_EXTI13_Pin */
  GPIO_InitStruct.Pin = BUTTON_EXTI13_Pin;
  GPIO_InitStruct.Mode = GPIO_MODE_IT_FALLING;
  GPIO_InitStruct.Pull = GPIO_NOPULL;
  HAL_GPIO_Init(BUTTON_EXTI13_GPIO_Port, &GPIO_InitStruct);

  /*Configure GPIO pins : ARD_A5_Pin ARD_A4_Pin ARD_A3_Pin ARD_A2_Pin
                           ARD_A1_Pin ARD_A0_Pin */
  GPIO_InitStruct.Pin = ARD_A5_Pin|ARD_A4_Pin|ARD_A3_Pin|ARD_A2_Pin
                          |ARD_A1_Pin|ARD_A0_Pin;
  GPIO_InitStruct.Mode = GPIO_MODE_ANALOG_ADC_CONTROL;
  GPIO_InitStruct.Pull = GPIO_NOPULL;
  HAL_GPIO_Init(GPIOC, &GPIO_InitStruct);

  /*Configure GPIO pins : ARD_D1_Pin ARD_D0_Pin */
  GPIO_InitStruct.Pin = ARD_D1_Pin|ARD_D0_Pin;
  GPIO_InitStruct.Mode = GPIO_MODE_AF_PP;
  GPIO_InitStruct.Pull = GPIO_NOPULL;
  GPIO_InitStruct.Speed = GPIO_SPEED_FREQ_VERY_HIGH;
  GPIO_InitStruct.Alternate = GPIO_AF8_UART4;
  HAL_GPIO_Init(GPIOA, &GPIO_InitStruct);

  /*Configure GPIO pins : ARD_D10_Pin SPBTLE_RF_RST_Pin ARD_D9_Pin */
  GPIO_InitStruct.Pin = ARD_D10_Pin|SPBTLE_RF_RST_Pin|ARD_D9_Pin;
  GPIO_InitStruct.Mode = GPIO_MODE_OUTPUT_PP;
  GPIO_InitStruct.Pull = GPIO_NOPULL;
  GPIO_InitStruct.Speed = GPIO_SPEED_FREQ_LOW;
  HAL_GPIO_Init(GPIOA, &GPIO_InitStruct);

  /*Configure GPIO pin : ARD_D4_Pin */
  GPIO_InitStruct.Pin = ARD_D4_Pin;
  GPIO_InitStruct.Mode = GPIO_MODE_AF_PP;
  GPIO_InitStruct.Pull = GPIO_NOPULL;
  GPIO_InitStruct.Speed = GPIO_SPEED_FREQ_LOW;
  GPIO_InitStruct.Alternate = GPIO_AF1_TIM2;
  HAL_GPIO_Init(ARD_D4_GPIO_Port, &GPIO_InitStruct);

  /*Configure GPIO pin : ARD_D7_Pin */
  GPIO_InitStruct.Pin = ARD_D7_Pin;
  GPIO_InitStruct.Mode = GPIO_MODE_ANALOG_ADC_CONTROL;
  GPIO_InitStruct.Pull = GPIO_NOPULL;
  HAL_GPIO_Init(ARD_D7_GPIO_Port, &GPIO_InitStruct);

  /*Configure GPIO pins : ARD_D13_Pin ARD_D12_Pin ARD_D11_Pin */
  GPIO_InitStruct.Pin = ARD_D13_Pin|ARD_D12_Pin|ARD_D11_Pin;
  GPIO_InitStruct.Mode = GPIO_MODE_AF_PP;
  GPIO_InitStruct.Pull = GPIO_NOPULL;
  GPIO_InitStruct.Speed = GPIO_SPEED_FREQ_VERY_HIGH;
  GPIO_InitStruct.Alternate = GPIO_AF5_SPI1;
  HAL_GPIO_Init(GPIOA, &GPIO_InitStruct);

  /*Configure GPIO pin : ARD_D3_Pin */
  GPIO_InitStruct.Pin = ARD_D3_Pin;
  GPIO_InitStruct.Mode = GPIO_MODE_INPUT;
  GPIO_InitStruct.Pull = GPIO_NOPULL;
  HAL_GPIO_Init(ARD_D3_GPIO_Port, &GPIO_InitStruct);

  /*Configure GPIO pin : ARD_D6_Pin */
  GPIO_InitStruct.Pin = ARD_D6_Pin;
  GPIO_InitStruct.Mode = GPIO_MODE_ANALOG_ADC_CONTROL;
  GPIO_InitStruct.Pull = GPIO_NOPULL;
  HAL_GPIO_Init(ARD_D6_GPIO_Port, &GPIO_InitStruct);

  /*Configure GPIO pins : ARD_D8_Pin ISM43362_BOOT0_Pin ISM43362_WAKEUP_Pin LED2_Pin
                           SPSGRF_915_SDN_Pin ARD_D5_Pin SPSGRF_915_SPI3_CSN_Pin */
  GPIO_InitStruct.Pin = ARD_D8_Pin|ISM43362_BOOT0_Pin|ISM43362_WAKEUP_Pin|LED2_Pin
                          |SPSGRF_915_SDN_Pin|ARD_D5_Pin|SPSGRF_915_SPI3_CSN_Pin;
  GPIO_InitStruct.Mode = GPIO_MODE_OUTPUT_PP;
  GPIO_InitStruct.Pull = GPIO_NOPULL;
  GPIO_InitStruct.Speed = GPIO_SPEED_FREQ_LOW;
  HAL_GPIO_Init(GPIOB, &GPIO_InitStruct);

  /*Configure GPIO pins : LPS22HB_INT_DRDY_EXTI0_Pin LSM6DSL_INT1_EXTI11_Pin ARD_D2_Pin HTS221_DRDY_EXTI15_Pin
                           PMOD_IRQ_EXTI12_Pin */
  GPIO_InitStruct.Pin = LPS22HB_INT_DRDY_EXTI0_Pin|LSM6DSL_INT1_EXTI11_Pin|ARD_D2_Pin|HTS221_DRDY_EXTI15_Pin
                          |PMOD_IRQ_EXTI12_Pin;
  GPIO_InitStruct.Mode = GPIO_MODE_INPUT;
  GPIO_InitStruct.Pull = GPIO_NOPULL;
  HAL_GPIO_Init(GPIOD, &GPIO_InitStruct);

  /*Configure GPIO pins : USB_OTG_FS_PWR_EN_Pin SPBTLE_RF_SPI3_CSN_Pin PMOD_RESET_Pin STSAFE_A100_RESET_Pin */
  GPIO_InitStruct.Pin = USB_OTG_FS_PWR_EN_Pin|SPBTLE_RF_SPI3_CSN_Pin|PMOD_RESET_Pin|STSAFE_A100_RESET_Pin;
  GPIO_InitStruct.Mode = GPIO_MODE_OUTPUT_PP;
  GPIO_InitStruct.Pull = GPIO_NOPULL;
  GPIO_InitStruct.Speed = GPIO_SPEED_FREQ_LOW;
  HAL_GPIO_Init(GPIOD, &GPIO_InitStruct);

  /*Configure GPIO pins : VL53L0X_XSHUT_Pin LED3_WIFI__LED4_BLE_Pin */
  GPIO_InitStruct.Pin = VL53L0X_XSHUT_Pin|LED3_WIFI__LED4_BLE_Pin;
  GPIO_InitStruct.Mode = GPIO_MODE_OUTPUT_PP;
  GPIO_InitStruct.Pull = GPIO_NOPULL;
  GPIO_InitStruct.Speed = GPIO_SPEED_FREQ_LOW;
  HAL_GPIO_Init(GPIOC, &GPIO_InitStruct);

  /*Configure GPIO pins : VL53L0X_GPIO1_EXTI7_Pin LSM3MDL_DRDY_EXTI8_Pin */
  GPIO_InitStruct.Pin = VL53L0X_GPIO1_EXTI7_Pin|LSM3MDL_DRDY_EXTI8_Pin;
  GPIO_InitStruct.Mode = GPIO_MODE_INPUT;
  GPIO_InitStruct.Pull = GPIO_NOPULL;
  HAL_GPIO_Init(GPIOC, &GPIO_InitStruct);

  /*Configure GPIO pin : PMOD_SPI2_SCK_Pin */
  GPIO_InitStruct.Pin = PMOD_SPI2_SCK_Pin;
  GPIO_InitStruct.Mode = GPIO_MODE_AF_PP;
  GPIO_InitStruct.Pull = GPIO_NOPULL;
  GPIO_InitStruct.Speed = GPIO_SPEED_FREQ_VERY_HIGH;
  GPIO_InitStruct.Alternate = GPIO_AF5_SPI2;
  HAL_GPIO_Init(PMOD_SPI2_SCK_GPIO_Port, &GPIO_InitStruct);

  /*Configure GPIO pins : PMOD_UART2_CTS_Pin PMOD_UART2_RTS_Pin PMOD_UART2_TX_Pin PMOD_UART2_RX_Pin */
  GPIO_InitStruct.Pin = PMOD_UART2_CTS_Pin|PMOD_UART2_RTS_Pin|PMOD_UART2_TX_Pin|PMOD_UART2_RX_Pin;
  GPIO_InitStruct.Mode = GPIO_MODE_AF_PP;
  GPIO_InitStruct.Pull = GPIO_NOPULL;
  GPIO_InitStruct.Speed = GPIO_SPEED_FREQ_VERY_HIGH;
  GPIO_InitStruct.Alternate = GPIO_AF7_USART2;
  HAL_GPIO_Init(GPIOD, &GPIO_InitStruct);

  /*Configure GPIO pins : ARD_D15_Pin ARD_D14_Pin */
  GPIO_InitStruct.Pin = ARD_D15_Pin|ARD_D14_Pin;
  GPIO_InitStruct.Mode = GPIO_MODE_AF_OD;
  GPIO_InitStruct.Pull = GPIO_NOPULL;
  GPIO_InitStruct.Speed = GPIO_SPEED_FREQ_VERY_HIGH;
  GPIO_InitStruct.Alternate = GPIO_AF4_I2C1;
  HAL_GPIO_Init(GPIOB, &GPIO_InitStruct);

  /* EXTI interrupt init*/
  HAL_NVIC_SetPriority(EXTI9_5_IRQn, 0, 0);
  HAL_NVIC_EnableIRQ(EXTI9_5_IRQn);

  HAL_NVIC_SetPriority(EXTI15_10_IRQn, 0, 0);
  HAL_NVIC_EnableIRQ(EXTI15_10_IRQn);

}

void Error_Handler(void)
{
  __disable_irq();
  while (1)
  {
  }
}
